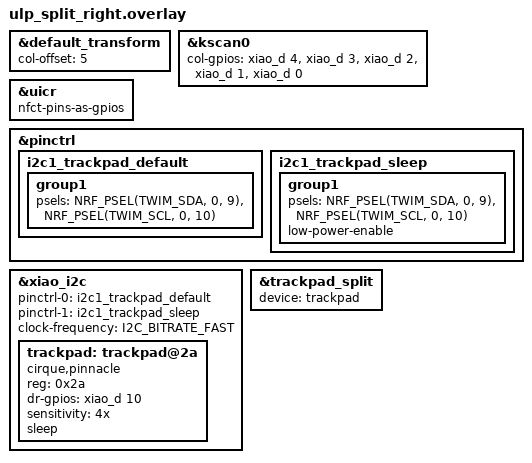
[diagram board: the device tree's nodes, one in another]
#include <dt-bindings/i2c/i2c.h>
#include <dt-bindings/pinctrl/nrf-pinctrl.h>
#include "ulp_split.dtsi"

&default_transform {
    col-offset = <5>;
};

&kscan0 {
    col-gpios
        = <&xiao_d 4 GPIO_ACTIVE_HIGH>
        , <&xiao_d 3 GPIO_ACTIVE_HIGH>
        , <&xiao_d 2 GPIO_ACTIVE_HIGH>
        , <&xiao_d 1 GPIO_ACTIVE_HIGH>
        , <&xiao_d 0 GPIO_ACTIVE_HIGH>
        ;
};

/*
 * Trackpad: Cirque Pinnacle (TM040040, I2C mode = R1 not fitted) on the TP1 pads below the XIAO.
 * SDA = NFC1 (P0.09), SCL = NFC2 (P0.10), DR = D10; 4.7k pull-ups on the PCB.
 */
&uicr {
    nfct-pins-as-gpios;
};

&pinctrl {
    i2c1_trackpad_default: i2c1_trackpad_default {
        group1 {
            psels = <NRF_PSEL(TWIM_SDA, 0, 9)>,
                    <NRF_PSEL(TWIM_SCL, 0, 10)>;
        };
    };

    i2c1_trackpad_sleep: i2c1_trackpad_sleep {
        group1 {
            psels = <NRF_PSEL(TWIM_SDA, 0, 9)>,
                    <NRF_PSEL(TWIM_SCL, 0, 10)>;
            low-power-enable;
        };
    };
};

&xiao_i2c {
    status = "okay";
    pinctrl-0 = <&i2c1_trackpad_default>;
    pinctrl-1 = <&i2c1_trackpad_sleep>;
    pinctrl-names = "default", "sleep";
    clock-frequency = <I2C_BITRATE_FAST>;

    trackpad: trackpad@2a {
        compatible = "cirque,pinnacle";
        reg = <0x2a>;
        status = "okay";
        dr-gpios = <&xiao_d 10 GPIO_ACTIVE_HIGH>;
        sensitivity = "4x";
        // hardware sleep after 5 s without a finger
        sleep;
    };
};

&trackpad_split {
    device = <&trackpad>;
};
